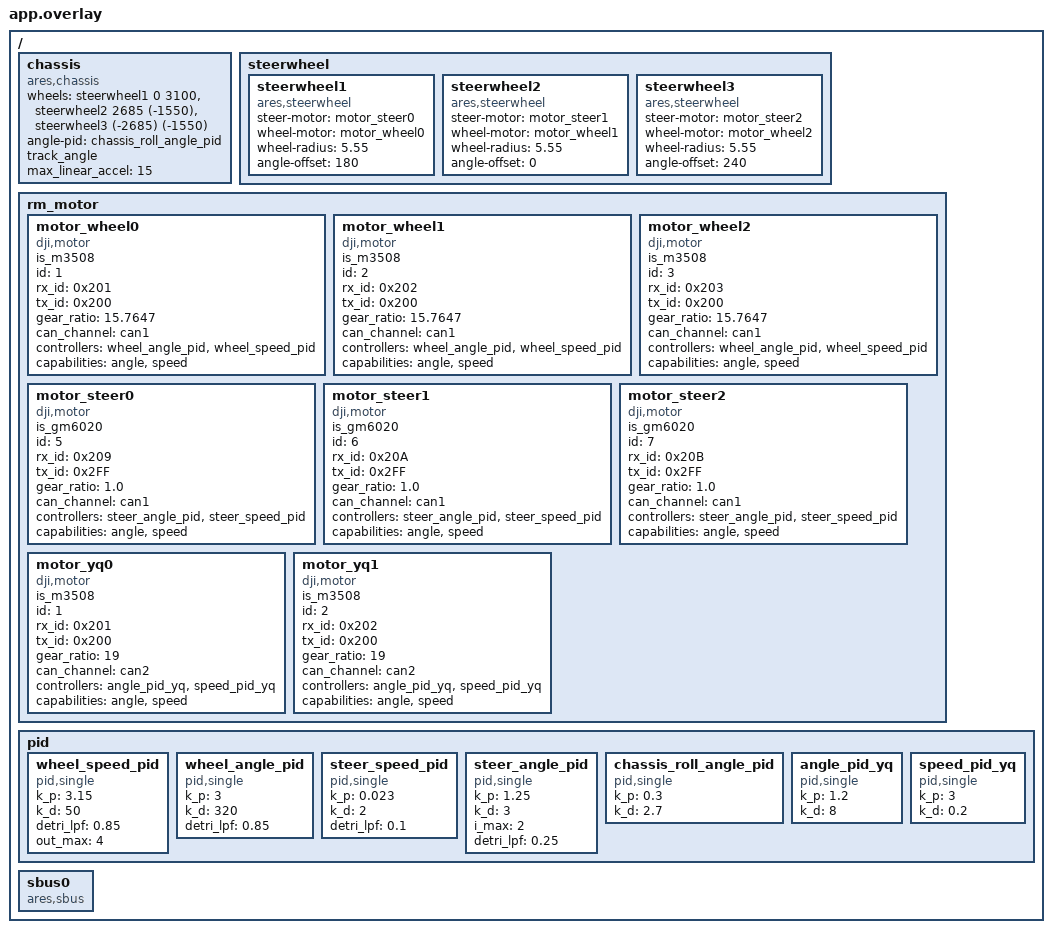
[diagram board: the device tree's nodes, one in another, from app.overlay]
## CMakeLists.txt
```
# SPDX-License-Identifier: Apache-2.0

cmake_minimum_required(VERSION 3.20.0)
set(CMAKE_CXX_STANDARD 17)
find_package(Zephyr REQUIRED HINTS $ENV{ZEPHYR_BASE})
project(motor)

FILE(GLOB app_sources src/*.c)

include_directories(${ZEPHYR_BASE}/include)
include_directories(${CMAKE_CURRENT_SOURCE_DIR}/include)
include_directories(${CMAKE_CURRENT_SOURCE_DIR}/dts)
target_sources(app PRIVATE ${app_sources})
target_include_directories(app PRIVATE ${ZEPHYR_BASE}/include)
target_include_directories(app PRIVATE ${CMAKE_CURRENT_SOURCE_DIR}/include)
target_include_directories(app PRIVATE ${CMAKE_CURRENT_SOURCE_DIR}/dts)
```

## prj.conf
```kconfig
# 禁用优化
# CONFIG_NO_OPTIMIZATIONS=n
# CONFIG_COMPILER_OPT="-O3 -fno-strict-overflow -fno-common -ffunction-sections -fdata-sections -ffreestanding -fno-builtin"

# 启用驱动
CONFIG_MOTOR=y
CONFIG_MOTOR_COMMON=y
CONFIG_MOTOR_DJI=y
CONFIG_MOTOR_DM=y
CONFIG_MOTOR_LOG_LEVEL=4
CONFIG_CAN=y
CONFIG_MOTOR_INIT_PRIORITY=90

CONFIG_ARES=y
CONFIG_ARES_SBUS=y
CONFIG_EKF_LIB=y

CONFIG_AUTO_PROBE_GYRO_BIAS=y

CONFIG_CHASSIS=y

CONFIG_DUAL_PROPOSE_PROTOCOL=y
CONFIG_UART_INTERFACE=y
CONFIG_USB_BULK_INTERFACE=y

# CONFIG_SEGGER_SYSTEMVIEW=y

# CONFIG_TRACING_SYSCALL=n

CONFIG_UDC_DRIVER_LOG_LEVEL_WRN=y
CONFIG_USBD_LOG_LEVEL_WRN=y

CONFIG_LOG=y
CONFIG_CONSOLE=y

# CONFIG_PLOTTER=y
# CONFIG_PLOTTER_FREQ=1000

CONFIG_CMSIS_DSP_QUATERNIONMATH=y
```

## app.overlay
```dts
/ {
	chassis: chassis {
		compatible = "ares,chassis";
		status = "okay";
		wheels = <&steerwheel1  0 3100>,
				<&steerwheel2 2685 (-1550)>,
				<&steerwheel3 (-2685) (-1550)>;
		angle-pid = <&chassis_roll_angle_pid>;
		track_angle;
		max_linear_accel = "15";
	};
	steerwheel {
		steerwheel1: steerwheel1 {
			#wheel-cells = <2>;
			compatible = "ares,steerwheel";
			status = "okay";
			steer-motor = <&motor_steer0>;
			wheel-motor = <&motor_wheel0>;
			wheel-radius = "5.55";
			angle-offset = "180";
		};

		steerwheel2: steerwheel2 {
			#wheel-cells = <2>;
			compatible = "ares,steerwheel";
			status = "okay";
			steer-motor = <&motor_steer1>;
			wheel-motor = <&motor_wheel1>;
			wheel-radius = "5.55";
			angle-offset = "0";
		};

		steerwheel3: steerwheel3 {
			#wheel-cells = <2>;
			compatible = "ares,steerwheel";
			status = "okay";
			steer-motor = <&motor_steer2>;
			wheel-motor = <&motor_wheel2>;
			wheel-radius = "5.55";
			angle-offset = "240";
		};
	};

	rm_motor {
		motor_wheel0: motor_wheel0{
			compatible = "dji,motor";
            is_m3508;
			id = <1>;
            rx_id = <0x201>;
            tx_id = <0x200>;
			gear_ratio = "15.7647";
			status = "okay";
			can_channel = <&can1>;
			controllers = <&wheel_angle_pid &wheel_speed_pid>;
			capabilities = "angle", "speed";
		};

		motor_wheel1: motor_wheel1{
			compatible = "dji,motor";
            is_m3508;
			id = <2>;
            rx_id = <0x202>;
            tx_id = <0x200>;
			gear_ratio = "15.7647";
			status = "okay";
			can_channel = <&can1>;
			controllers = <&wheel_angle_pid &wheel_speed_pid>;
			capabilities = "angle", "speed";
		};

		motor_wheel2: motor_wheel2{
			compatible = "dji,motor";
            is_m3508;
			id = <3>;
            rx_id = <0x203>;
            tx_id = <0x200>;
			gear_ratio = "15.7647";
			status = "okay";
			can_channel = <&can1>;
			controllers = <&wheel_angle_pid &wheel_speed_pid>;
			capabilities = "angle", "speed";
		};

		motor_steer0: motor_steer0{
			compatible = "dji,motor";
			is_gm6020;
			id = <5>;
			rx_id = <0x209>;
			tx_id = <0x2FF>;
			gear_ratio = "1.0";
			status = "okay";
			can_channel = <&can1>;
			controllers = <&steer_angle_pid &steer_speed_pid>;
			capabilities = "angle", "speed";
		};

		motor_steer1: motor_steer1{
			compatible = "dji,motor";
			is_gm6020;
			id = <6>;
			rx_id = <0x20A>;
			tx_id = <0x2FF>;
			gear_ratio = "1.0";
			status = "okay";
			can_channel = <&can1>;
			controllers = <&steer_angle_pid &steer_speed_pid>;
			capabilities = "angle", "speed";
		};

		motor_steer2: motor_steer2{
			compatible = "dji,motor";
			is_gm6020;
			id = <7>;
			rx_id = <0x20B>;
			tx_id = <0x2FF>;
			gear_ratio = "1.0";
			status = "okay";
			can_channel = <&can1>;
			controllers = <&steer_angle_pid &steer_speed_pid>;
			capabilities = "angle", "speed";
		};

		motor_yq0: motor_yq0 {
			compatible = "dji,motor";
			is_m3508;
			id = <1>;
			rx_id = <0x201>;
			tx_id = <0x200>;
			gear_ratio = "19";
			status = "okay";
			can_channel = <&can2>;
			controllers = <&angle_pid_yq &speed_pid_yq>;
			capabilities = "angle", "speed";
		};

		motor_yq1: motor_yq1 {
			compatible = "dji,motor";
			is_m3508;
			id = <2>;
			rx_id = <0x202>;
			tx_id = <0x200>;
			gear_ratio = "19";
			status = "okay";
			can_channel = <&can2>;
			controllers = <&angle_pid_yq &speed_pid_yq>;
			capabilities = "angle", "speed";
		};
	};

	pid {
		wheel_speed_pid: wheel_speed_pid {
			#controller-cells = <0>;
			compatible = "pid,single";
			k_p = "3.15";
			k_d = "50";
			detri_lpf = "0.85";
			out_max = "4";
		};

		wheel_angle_pid: wheel_angle_pid {
			#controller-cells = <0>;
			compatible = "pid,single";
			k_p = "3";
			k_d = "320";
			detri_lpf = "0.85";
		};

		steer_speed_pid: steer_speed_pid {
			#controller-cells = <0>;
			compatible = "pid,single";
			k_p = "0.023";
			k_d = "2";
			detri_lpf = "0.1";
		};

		steer_angle_pid: steer_angle_pid {
			#controller-cells = <0>;
			compatible = "pid,single";
			k_p = "1.25";
			k_d = "3";
			i_max = "2";
			detri_lpf = "0.25";
		};

		chassis_roll_angle_pid: chassis_roll_angle_pid {
			#controller-cells = <0>;
			compatible = "pid,single";
			k_p = "0.3";
			k_d = "2.7";
		};

		angle_pid_yq: angle_pid_yq {
			#controller-cells = <0>;
			compatible = "pid,single";
			k_p = "1.2";
			k_d = "8";
		};
		speed_pid_yq: speed_pid_yq {
			#controller-cells = <0>;
			compatible = "pid,single";
			k_p = "3";
			k_d = "0.2";
		};
	};
	
	sbus0: sbus0 {
		compatible = "ares,sbus";
		status = "okay";
	};
};
```

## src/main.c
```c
#include <math.h>
#include <stdbool.h>
#include <stddef.h>
#include <stdint.h>
#include <zephyr/device.h>
#include <zephyr/logging/log.h>
#include <zephyr/kernel.h>
#include <zephyr/drivers/motor.h>
#include <zephyr/drivers/sbus.h>
#include <zephyr/drivers/chassis.h>
#include <ares/board/init.h>
#include <ares/ekf/imu_task.h>
#include <ares/interface/usb/usb_bulk.h>
#include <ares/protocol/dual/dual_protocol.h>
#include <ares/ares_comm.h>
#include <sys/_stdint.h>
#include "ares/ekf/QuaternionEKF.h"
#include "devices.h"
#include <arm_math.h>

LOG_MODULE_REGISTER(main, LOG_LEVEL_DBG);
#ifndef M_PI
#define M_PI 3.14159265f
#endif

int pub_cnt = 0;
#define CHASSIS_SRC_SBUS
static volatile bool yunqiu_in_progress = false;  // 运球进行中标志
static volatile bool allow_rotation_only = false; // 仅允许旋转标志

void Sensor_update_cb(QEKF_INS_t *QEKF)
{
	struct pos_data pos = {0};

	pos.accel[0] = QEKF->Accel[X];
	pos.accel[1] = QEKF->Accel[Y];
	pos.accel[2] = QEKF->Accel[Z];
	pos.Yaw = QEKF->Yaw;
	
	if (pub_cnt++ % 2) {
		// chassis_update_sensor(chassis, &pos);
	}
}


void yunqiu_low(void)
{
	LOG_INF("Yunqiu low operation...");

	// 设置运球进行中标志 - 允许旋转，禁止移动
	yunqiu_in_progress = true;
	allow_rotation_only = true;

	k_msleep(200);

	// 第一阶段：准备
	motor_set_torque(yq1, 9.5);
	motor_set_torque(yq3, -9.5);
	k_msleep(200);

	// 第二阶段：运动
	motor_set_speed(yq1, -150);
	motor_set_speed(yq3, 150);
	k_msleep(400);

	// 停止
	motor_set_speed(yq1, 0);
	motor_set_speed(yq3, 0);
	k_msleep(200);

	// 清除标志 - 恢复完全控制
	yunqiu_in_progress = false;
	allow_rotation_only = false;

	LOG_INF("Yunqiu low operation completed");
}

void takein_low()
{
	LOG_INF("Takein low...");

	// 取球时也可以允许旋转
	yunqiu_in_progress = true;
	allow_rotation_only = true;

	motor_set_speed(yq1, -150);
	motor_set_speed(yq3, 150);
	k_msleep(200);
	motor_set_speed(yq1, 0);
	motor_set_speed(yq3, 0);

	// 恢复控制
	yunqiu_in_progress = false;
	allow_rotation_only = false;

	LOG_INF("Takein low completed");
}

void console_feedback(void *arg1, void *arg2, void *arg3)
{
	float angvel = 0;
	int cnt = 0;
	bool zeroed = false;

	while (1) {
		k_msleep(4);

#ifdef CHASSIS_SRC_SBUS
		angvel = -sbus_get_percent(sbus, 0);
		float X = -sbus_get_percent(sbus, 3);
		float Y = -sbus_get_percent(sbus, 1);

		// 死区处理
		float linear_magnitude = sqrtf(X * X + Y * Y);
		bool in_deadzone = ((linear_magnitude < 0.06f) && (fabsf(angvel) < 0.06f));
		bool rotation_only = (linear_magnitude < 0.06f) && (fabsf(angvel) >= 0.06f);

		// 检查运球状态并相应控制底盘
		if (yunqiu_in_progress && allow_rotation_only) {
			// 运球进行中：禁止移动，允许旋转
			if (rotation_only) {
				// 只有旋转输入，允许旋转
				chassis_set_static(chassis, false);
				chassis_set_speed(chassis, 0, 0); // 强制零移动
				chassis_set_gyro(chassis, angvel * 2.0f);
				zeroed = false;
				LOG_DBG("Yunqiu mode: Rotation allowed, X=0, Y=0, Gyro=%.2f",
					(double)angvel);
			} else if (fabsf(angvel) < 0.06f) {
				// 无旋转输入，完全静止
				chassis_set_static(chassis, true);
				zeroed = true;
			} else {
				// 有移动和旋转输入，只执行旋转
				chassis_set_static(chassis, false);
				chassis_set_speed(chassis, 0, 0); // 强制零移动
				chassis_set_gyro(chassis, angvel * 2.0f);
				zeroed = false;
				LOG_DBG("Yunqiu mode: Only rotation, Gyro=%.2f", (double)angvel);
			}
		} else if (in_deadzone) {
			// 正常死区处理
			chassis_set_static(chassis, true);
			zeroed = true;
		} else {
			// 正常底盘控制（移动+旋转）
			chassis_set_static(chassis, false);
			chassis_set_speed(chassis, -X * 2.0f, -Y * 2.0f);
			chassis_set_gyro(chassis, angvel * 2.0f);
			zeroed = false;
		}

		if (cnt++ % 2000 == 0) {
			if (yunqiu_in_progress && allow_rotation_only) {
				LOG_INF("Manual: ROTATION ONLY (yunqiu) - Gyro=%.1f",
					(double)angvel);
			} else if (yunqiu_in_progress) {
				LOG_INF("Manual: BLOCKED (yunqiu in progress)");
			} else {
				LOG_INF("Manual: X=%.1f Y=%.1f Gyro=%.1f", (double)X, (double)Y,
					(double)angvel);
			}
		}
#endif
	}
}


K_THREAD_DEFINE(feedback_thread, 4096, console_feedback, NULL, NULL, NULL, 2, 0, 100);
uint32_t log_cnt;

int main(void)
{
	chassis_set_enabled(chassis, false);
	IMU_Sensor_trig_init(accel_dev, gyro_dev);
	k_msleep(100); // 减少等待时间
	IMU_Sensor_set_update_cb(Sensor_update_cb);
	chassis_set_enabled(chassis, true);
	chassis_set_gyro(chassis, 0);
	static bool sbus_states[6] = {false}; // 简化状态管理

	while (1) {
		// 读取SBUS
		float sbus_vals[6] = {
			sbus_get_percent(sbus, 4), // takein_up
			sbus_get_percent(sbus, 5), // yunqiu
			sbus_get_percent(sbus, 6), // shoot
		};

		// 统一的SBUS处理逻辑
		if (sbus_vals[0] > 0.0f && !sbus_states[0]) {
			yunqiu_low();
			k_msleep(50);
			yunqiu_low();
			sbus_states[0] = true;
		} else if (sbus_vals[0] <= 0.5f) {
			sbus_states[0] = false;
		}

		if (sbus_vals[1] > 0.0f && !sbus_states[1]) {
			takein_low();
			sbus_states[1] = true;
		} else if (sbus_vals[1] <= 0.5f) {
			sbus_states[1] = false;
		}

		if (sbus_vals[2] > 0.0f && !sbus_states[2]) {
			
			sbus_states[2] = true;
		} else if (sbus_vals[2] <= 0.5f) {
			sbus_states[2] = false;
		}

	

		k_msleep(10);

		// 简化日志
		if (++log_cnt % 2000 == 0) {
			const char *status = "";
			if (yunqiu_in_progress && allow_rotation_only) {
				status = " [ROTATION_ONLY]";
			} else if (yunqiu_in_progress) {
				status = " [BLOCKED]";
			}
			LOG_DBG("SBUS: [%.1f %.1f %.1f ]%s", (double)sbus_vals[0],
				(double)sbus_vals[1], (double)sbus_vals[2],  status);
		}
	}

	return 0;
}
```
